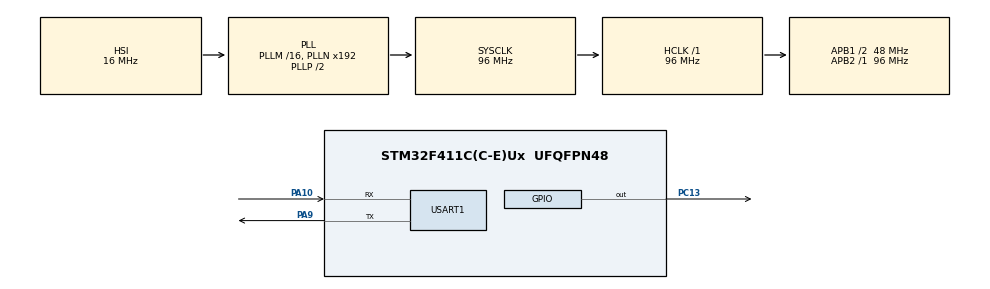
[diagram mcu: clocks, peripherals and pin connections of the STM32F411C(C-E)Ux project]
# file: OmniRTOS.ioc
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Mcu.Family=STM32F4
Mcu.Name=STM32F411C(C-E)Ux
Mcu.Package=UFQFPN48
NVIC.PriorityGroup=NVIC_PRIORITYGROUP_4
PA10.Mode=Asynchronous
PA10.Signal=USART1_RX
PA13.Mode=Serial_Wire
PA13.Signal=SYS_JTMS-SWDIO
PA14.Mode=Serial_Wire
PA14.Signal=SYS_JTCK-SWCLK
PA9.Mode=Asynchronous
PA9.Signal=USART1_TX
PC13-ANTI_TAMP.Signal=GPIO_Output
PC14-OSC32_IN.Mode=LSE-External-Oscillator
PC14-OSC32_IN.Signal=RCC_OSC32_IN
PC15-OSC32_OUT.Mode=LSE-External-Oscillator
PC15-OSC32_OUT.Signal=RCC_OSC32_OUT
PH0\ -\ OSC_IN.Mode=HSE-External-Oscillator
PH0\ -\ OSC_IN.Signal=RCC_OSC_IN
PH1\ -\ OSC_OUT.Mode=HSE-External-Oscillator
PH1\ -\ OSC_OUT.Signal=RCC_OSC_OUT
ProjectManager.HeapSize=0x200
ProjectManager.StackSize=0x400
ProjectManager.TargetToolchain=CMake
RCC.AHBFreq_Value=96000000
RCC.APB1CLKDivider=RCC_HCLK_DIV2
RCC.APB1Freq_Value=48000000
RCC.APB1TimFreq_Value=96000000
RCC.APB2Freq_Value=96000000
RCC.APB2TimFreq_Value=96000000
RCC.CortexFreq_Value=96000000
RCC.HCLKFreq_Value=96000000
RCC.HSE_VALUE=25000000
RCC.HSI_VALUE=16000000
RCC.SYSCLKFreq_VALUE=96000000
RCC.SYSCLKSource=RCC_SYSCLKSOURCE_PLLCLK
RCC.VCOOutputFreq_Value=192000000
USART1.VirtualMode=VM_ASYNC
board=custom

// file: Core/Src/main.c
/* USER CODE BEGIN Header */
/**
  ******************************************************************************
  * @file           : main.c
  * @brief          : Main program body
  ******************************************************************************
  * @attention
  *
  * Copyright (c) 2026 STMicroelectronics.
  * All rights reserved.
  *
  * This software is licensed under terms that can be found in the LICENSE file
  * in the root directory of this software component.
  * If no LICENSE file comes with this software, it is provided AS-IS.
  *
  ******************************************************************************
  */
/* USER CODE END Header */
#include "main.h"
#include "usart.h"
#include "gpio.h"
#include "os_task.h"

/* USER CODE BEGIN PTD */

/* 声明内核函数 */
extern void os_sched_remove(os_task_t *task);
extern void os_sched_insert(os_task_t *task);
extern void os_schedule(void);
extern void os_system_start(void);
/* USER CODE END PTD */

/* USER CODE BEGIN PM */
os_task_t task1;
os_task_t task2;
uint8_t task1_stack[512];
uint8_t task2_stack[512];
static void delay_cycles(volatile uint32_t count) {
    while(count--) {
        __asm volatile("nop");
    }
}
/* Task2：高优先级任务 */
void task2_entry(void *param) {
    while (1) {
        /* 执行高优先级业务逻辑 ... */
        delay_cycles(1000000);

        /* 模拟挂起自己：切回 Task1 */
        os_sched_remove(&task2);
        os_schedule();
    }
}

/* Task1：低优先级任务 */
void task1_entry(void *param) {
    while (1) {
        /* 执行低优先级业务逻辑 ... */
        delay_cycles(5000000);

        /* 唤醒高优先级任务：立即产生抢占 */
        os_sched_insert(&task2);
        os_schedule();
    }
}

/* USER CODE END PM */

void SystemClock_Config(void);

int main(void)
{

  /* MCU Configuration--------------------------------------------------------*/

  /* Reset of all peripherals, Initializes the Flash interface and the Systick. */
  HAL_Init();

  /* Configure the system clock */
  SystemClock_Config();

  /* Initialize all configured peripherals */
  MX_GPIO_Init();
  MX_USART1_UART_Init();

  /* Infinite loop */
  /* USER CODE BEGIN WHILE */
   os_task_init(&task1, "task1", task1_entry, OS_NULL,
                 &task1_stack[0], sizeof(task1_stack), 10);

    /* 任务 2：优先级 5 (比任务 1 优先级高) */
    os_task_init(&task2, "task2", task2_entry, OS_NULL,
                 &task2_stack[0], sizeof(task2_stack), 5);

    /* 2. 插入就绪队列 */
    os_sched_insert(&task1);

    /* 注意：此时由于 task2 尚未插入，系统启动后会优先运行 task1。
       task1 运行一段时间后，会唤醒 task2，从而演示抢占效果。*/

    /* 3. 移交控制权给 OS (此函数不返回) */
    os_system_start();
  /* USER CODE END 3 */
}

void SystemClock_Config(void)
{
  RCC_OscInitTypeDef RCC_OscInitStruct = {0};
  RCC_ClkInitTypeDef RCC_ClkInitStruct = {0};

  /** Configure the main internal regulator output voltage
  */
  __HAL_RCC_PWR_CLK_ENABLE();
  __HAL_PWR_VOLTAGESCALING_CONFIG(PWR_REGULATOR_VOLTAGE_SCALE1);

  /** Initializes the RCC Oscillators according to the specified parameters
  * in the RCC_OscInitTypeDef structure.
  */
  RCC_OscInitStruct.OscillatorType = RCC_OSCILLATORTYPE_HSI;
  RCC_OscInitStruct.HSIState = RCC_HSI_ON;
  RCC_OscInitStruct.HSICalibrationValue = RCC_HSICALIBRATION_DEFAULT;
  RCC_OscInitStruct.PLL.PLLState = RCC_PLL_ON;
  RCC_OscInitStruct.PLL.PLLSource = RCC_PLLSOURCE_HSI;
  RCC_OscInitStruct.PLL.PLLM = 16;
  RCC_OscInitStruct.PLL.PLLN = 192;
  RCC_OscInitStruct.PLL.PLLP = RCC_PLLP_DIV2;
  RCC_OscInitStruct.PLL.PLLQ = 4;
  if (HAL_RCC_OscConfig(&RCC_OscInitStruct) != HAL_OK)
  {
    Error_Handler();
  }

  /** Initializes the CPU, AHB and APB buses clocks
  */
  RCC_ClkInitStruct.ClockType = RCC_CLOCKTYPE_HCLK|RCC_CLOCKTYPE_SYSCLK
                              |RCC_CLOCKTYPE_PCLK1|RCC_CLOCKTYPE_PCLK2;
  RCC_ClkInitStruct.SYSCLKSource = RCC_SYSCLKSOURCE_PLLCLK;
  RCC_ClkInitStruct.AHBCLKDivider = RCC_SYSCLK_DIV1;
  RCC_ClkInitStruct.APB1CLKDivider = RCC_HCLK_DIV2;
  RCC_ClkInitStruct.APB2CLKDivider = RCC_HCLK_DIV1;

  if (HAL_RCC_ClockConfig(&RCC_ClkInitStruct, FLASH_LATENCY_3) != HAL_OK)
  {
    Error_Handler();
  }
}

void Error_Handler(void)
{
  __disable_irq();
  while (1)
  {
  }
}
